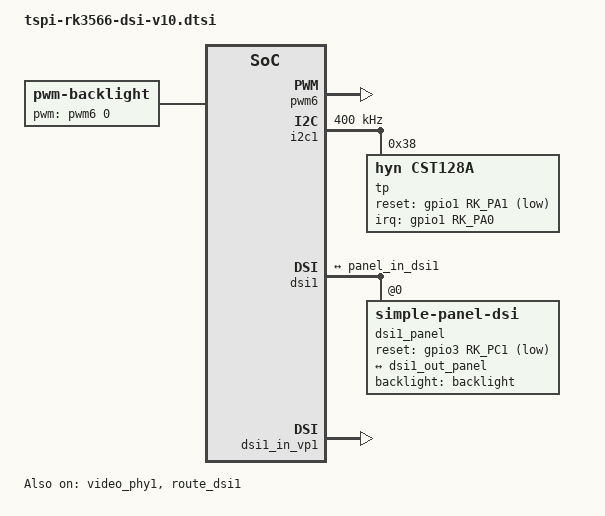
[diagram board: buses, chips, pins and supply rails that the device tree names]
/*********************************************************************
 *           立创开发板不靠卖板赚钱，以培养中国工程师为己任  
 *         泰山派软硬件资料与相关扩展板软硬件资料官网全部开源
 *                      开发板官网：www.lckfb.com            
 *                     立创论坛：oshwhub.com/forum           
 *            关注B站：【立创开发板】，掌握我们的最新动态！  
 *********************************************************************
 * 文件名：tspi-rk3566-dsi-v10.dtsi
 * 描述：mipi 屏幕
 * 更新:
 * 时间          作者           联系           说明
 * 2023-09-13   吴才成    1378913492@qq.com   v1.0.0
 * 2024-01-19   风漠兮    578118086@qq.com    Fit D310T9362V1
 * 2024-06-08   千古长夜  36076779@qq.com     适配小海豚手机扩展版第二版，修改PWM输出为PWM6
 *********************************************************************/
/ {
	backlight: backlight {
		compatible = "pwm-backlight";
		pwms = <&pwm6 0 25000 0>;
		brightness-levels = <
			  0  20  20  21  21  22  22  23
			 23  24  24  25  25  26  26  27
			 27  28  28  29  29  30  30  31
			 31  32  32  33  33  34  34  35
			 35  36  36  37  37  38  38  39
			 40  41  42  43  44  45  46  47
			 48  49  50  51  52  53  54  55
			 56  57  58  59  60  61  62  63
			 64  65  66  67  68  69  70  71
			 72  73  74  75  76  77  78  79
			 80  81  82  83  84  85  86  87
			 88  89  90  91  92  93  94  95
			 96  97  98  99 100 101 102 103
			104 105 106 107 108 109 110 111
			112 113 114 115 116 117 118 119
			120 121 122 123 124 125 126 127
			128 129 130 131 132 133 134 135
			136 137 138 139 140 141 142 143
			144 145 146 147 148 149 150 151
			152 153 154 155 156 157 158 159
			160 161 162 163 164 165 166 167
			168 169 170 171 172 173 174 175
			176 177 178 179 180 181 182 183
			184 185 186 187 188 189 190 191
			192 193 194 195 196 197 198 199
			200 201 202 203 204 205 206 207
			208 209 210 211 212 213 214 215
			216 217 218 219 220 221 222 223
			224 225 226 227 228 229 230 231
			232 233 234 235 236 237 238 239
			240 241 242 243 244 245 246 247
			248 249 250 251 252 253 254 255
		>;
		default-brightness-level = <255>;
	};
};

&pwm6 {
	status = "okay";
};

&i2c1 {
	status = "okay";
	clock-frequency = <400000>;
	
	tp@38 {
		status = "okay";
		pinctrl-0 = <&touch_gpio>;
		compatible = "hyn,cst128a";
		reg = <0x38>;
		reset-gpios = <&gpio1 RK_PA1 GPIO_ACTIVE_LOW>;
		irq-gpios = <&gpio1 RK_PA0 IRQ_TYPE_LEVEL_LOW>;
	};
};


&pinctrl {
	dsi1 {
		dsi1_rst_gpio: dsi1-rst-gpio {
			rockchip,pins = <3 RK_PC1 RK_FUNC_GPIO &pcfg_pull_none>;
		};
		touch_gpio: touch-gpio {
			rockchip,pins = <1 RK_PA0 RK_FUNC_GPIO &pcfg_pull_up>;
		};
	};
};

/*
 * video_phy1 needs to be enabled
 * when dsi1 is enabled
 */
&dsi1 {
	status = "okay";
};

&dsi1_in_vp0 {
	status = "disabled";
};

&dsi1_in_vp1 {
	status = "okay";
};

&video_phy1 {
	status = "okay";
};

&route_dsi1 {
	status = "okay";//wucaicheng mipi okay
	connect = <&vp1_out_dsi1>;
};

// D310T9362V1
&dsi1 {
	status = "okay";
	rockchip,lane-rate = <480>;//(480+50+60+10)*(800+20+34+2)*60*3*8/2,+100mhz
	dsi1_panel: panel@0 {
		status = "okay";
		compatible = "simple-panel-dsi";
		reset-gpios = <&gpio3 RK_PC1 GPIO_ACTIVE_LOW>;
		pinctrl-names = "default";
		pinctrl-0 = <&dsi1_rst_gpio>;
		reg = <0>;
		backlight = <&backlight>;
		reset-delay-ms = <200>;
		enable-delay-ms = <100>;
		prepare-delay-ms = <20>;
		unprepare-delay-ms = <20>;
		disable-delay-ms = <20>;
		init-delay-ms = <120>;
		dsi,flags = <(MIPI_DSI_MODE_VIDEO | MIPI_DSI_MODE_VIDEO_BURST |
			MIPI_DSI_MODE_LPM | MIPI_DSI_MODE_EOT_PACKET)>;
		dsi,format = <MIPI_DSI_FMT_RGB888>;
		dsi,lanes  = <2>;
		panel-init-sequence = [
			// init code
			05 78 01 01
			05 78 01 11
			39 0A 06 FF 77 01 00 00 11
			15 0A 02 D1 11
			15 0A 02 55 B0 // 80 90 b0
			39 0A 06 FF 77 01 00 00 10
			39 0A 03 C0 63 00
			39 0A 03 C1 09 02
			39 0A 03 C2 37 08
			15 0A 02 C7 00 // x-dir rotate 0:0x00,rotate 180:0x04
			15 0A 02 CC 38
			39 0A 11 B0 00 11 19 0C 10 06 07 0A 09 22 04 10 0E 28 30 1C
			39 6E 11 B1 00 12 19 0D 10 04 06 07 08 23 04 12 11 28 30 1C
			39 0A 06 FF 77 01 00 00 11 // enable  bk fun of  command 2  BK1
			15 0A 02 B0 4D
			15 0A 02 B1 60 // 0x56  0x4a  0x5b
			15 0A 02 B2 07
			15 6E 02 B3 80
			15 0A 02 B5 47
			15 0A 02 B7 8A
			15 0A 02 B8 21
			15 0A 02 C1 78
			15 0A 02 C2 78
			15 0A 02 D0 88
			39 0A 04 E0 00 00 02
			39 0A 0C E1 01 A0 03 A0 02 A0 04 A0 00 44 44
			39 0A 0D E2 00 00 00 00 00 00 00 00 00 00 00 00
			39 0A 05 E3 00 00 33 33
			39 0A 03 E4 44 44
			39 0A 11 E5 01 26 A0 A0 03 28 A0 A0 05 2A A0 A0 07 2C A0 A0
			39 0A 05 E6 00 00 33 33
			39 0A 03 E7 44 44
			39 0A 11 E8 02 26 A0 A0 04 28 A0 A0 06 2A A0 A0 08 2C A0 A0
			39 0A 08 EB 00 01 E4 E4 44 00 40
			39 0A 11 ED FF F7 65 4F 0B A1 CF FF FF FC 1A B0 F4 56 7F FF
			15 0A 02 EE 42 // missing?
			39 0A 06 FF 77 01 00 00 00
			15 0A 02 36 00 //U&D  Y-DIR rotate 0:0x00,rotate 180:0x10
			15 0A 02 3A 55
			05 78 01 11           
			05 14 01 29		
		];

		panel-exit-sequence = [
			05 00 01 28
			05 00 01 10
		];

		disp_timings1: display-timings {
			native-mode = <&dsi1_timing0>;
			dsi1_timing0: timing0 {
				clock-frequency = <30816000>;// (480+50+60+10)*(800+20+34+2)*60

				hactive = <480>;
				hfront-porch = <50>;
				hback-porch = <60>;
				hsync-len = <10>;

				vactive = <800>;
				vfront-porch = <20>;
				vback-porch = <34>;
				vsync-len = <2>;

				hsync-active = <0>;
				vsync-active = <0>;
				de-active = <0>;
				pixelclk-active = <0>;

				swap-rb = <0>;
				swap-rg = <0>;
				swap-gb = <0>;
			};
		};

		ports {
			#address-cells = <1>;
			#size-cells = <0>;

			port@0 {
				reg = <0>;
				panel_in_dsi1: endpoint {
					remote-endpoint = <&dsi1_out_panel>;
				};
			};
		};
	};

	ports {
		#address-cells = <1>;
		#size-cells = <0>;

		port@1 {
			reg = <1>;
			dsi1_out_panel: endpoint {
				remote-endpoint = <&panel_in_dsi1>;
			};
		};
	};

};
